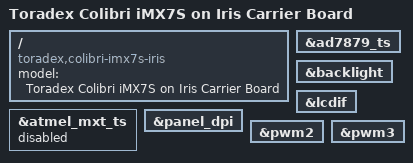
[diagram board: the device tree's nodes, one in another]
/dts-v1/;
#include "imx7s-colibri.dtsi"
#include "imx7-colibri-iris.dtsi"
/ {
	model = "Toradex Colibri iMX7S on Iris Carrier Board";
	compatible = "toradex,colibri-imx7s-iris",
		     "toradex,colibri-imx7s",
		     "fsl,imx7s";
};
&ad7879_ts {
	status = "okay";
};
&atmel_mxt_ts {
	status = "disabled";
};
&backlight {
	status = "okay";
};
&lcdif {
	status = "okay";
};
&panel_dpi {
	status = "okay";
};
&pwm2 {
	status = "okay";
};
&pwm3 {
	status = "okay";
};
